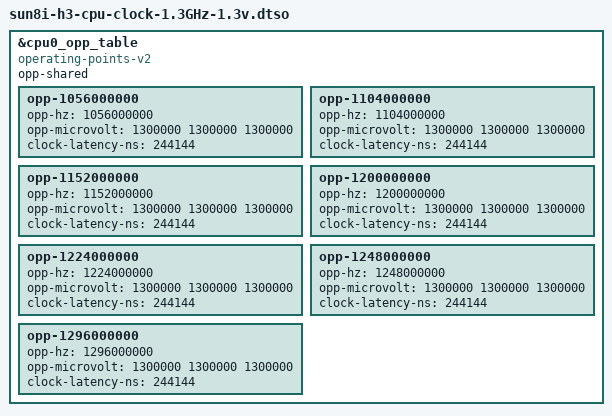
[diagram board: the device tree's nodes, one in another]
// DT overlay for CPU frequency operating points to 1.3GHz at a maximum CPU voltage of 1.3v

/dts-v1/;
/plugin/;

/ {
	fragment@0 {
		target = <&cpu0_opp_table>;

		__overlay__ {
			compatible = "operating-points-v2";
			opp-shared;

			// in order to match the DT cooling-maps, update the existing OP table in-place
			// with the new voltages

			opp-1056000000 {
				opp-hz = /bits/ 64 <1056000000>;
				opp-microvolt = <1300000 1300000 1300000>;
				clock-latency-ns = <244144>; /* 8 32k periods */
			};

			opp-1104000000 {
				opp-hz = /bits/ 64 <1104000000>;
				opp-microvolt = <1300000 1300000 1300000>;
				clock-latency-ns = <244144>; /* 8 32k periods */
			};

			opp-1152000000 {
				opp-hz = /bits/ 64 <1152000000>;
				opp-microvolt = <1300000 1300000 1300000>;
				clock-latency-ns = <244144>; /* 8 32k periods */
			};

			opp-1200000000 {
				opp-hz = /bits/ 64 <1200000000>;
				opp-microvolt = <1300000 1300000 1300000>;
				clock-latency-ns = <244144>; /* 8 32k periods */
			};

			opp-1224000000 {
				opp-hz = /bits/ 64 <1224000000>;
				opp-microvolt = <1300000 1300000 1300000>;
				clock-latency-ns = <244144>; /* 8 32k periods */
			};

			opp-1248000000 {
				opp-hz = /bits/ 64 <1248000000>;
				opp-microvolt = <1300000 1300000 1300000>;
				clock-latency-ns = <244144>; /* 8 32k periods */
			};

			opp-1296000000 {
				opp-hz = /bits/ 64 <1296000000>;
				opp-microvolt = <1300000 1300000 1300000>;
				clock-latency-ns = <244144>; /* 8 32k periods */
			};
		};
	};
};

